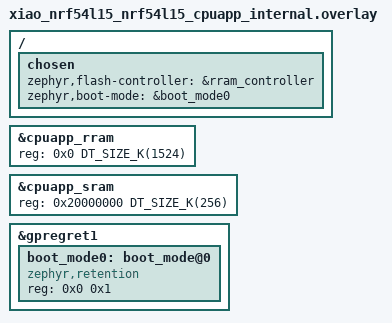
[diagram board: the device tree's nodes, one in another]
/*
 * Copyright (c) 2024 Nordic Semiconductor ASA
 *
 * SPDX-License-Identifier: LicenseRef-Nordic-5-Clause
 */

/ {
	chosen {
		zephyr,flash-controller = &rram_controller; /* from boards/nordic/nrf54l15dk/nrf54l_05_10_15_cpuapp_common.dtsi */
		zephyr,boot-mode = &boot_mode0;		    /* from boards/nordic/nrf54l15dk/nrf54l_05_10_15_cpuapp_common.dtsi */
	};
};

/* restore full RRAM and SRAM space - by default some parts are dedicated to FLRP */
&cpuapp_rram {
	reg = <0x0 DT_SIZE_K(1524)>;
};

&cpuapp_sram {
	reg = <0x20000000 DT_SIZE_K(256)>;
	ranges = <0x0 0x20000000 0x40000>;
};

/* begin: from boards/nordic/nrf54l15dk/nrf54l_05_10_15_cpuapp_common.dtsi */
&gpregret1 {
	status = "okay";

	boot_mode0: boot_mode@0 {
		compatible = "zephyr,retention";
		status = "okay";
		reg = <0x0 0x1>;
	};
};
/* end: from boards/nordic/nrf54l15dk/nrf54l_05_10_15_cpuapp_common.dtsi */
